# AE612FA0E5597BS0_CM55_HP_View register map
Vendor: Alif Semiconductor; Series: E6; File version: 1.0
CPU: CM55 r1p0, selectable endian, MPU, FPU, double-precision FPU, DSP, VTOR, 8 interrupt priority bits, 1 SAU regions
Registers are 32-bit, read-write, reset 0x0 unless marked. A register's access mark holds for its fields unless they carry their own. Offsets are from the block's base; [hi:lo] are bit positions; 'fields as' and 'values as' point back to an identical list.

## CLKCTL_PER_MST
Base 0x4903F000
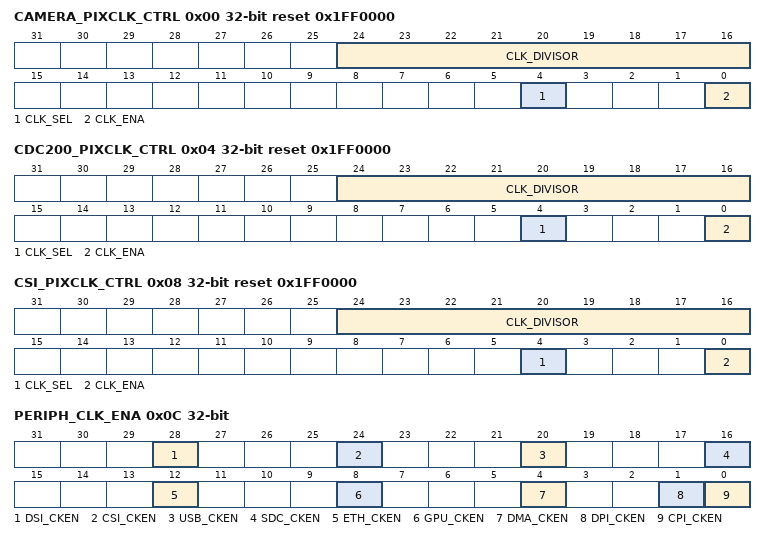
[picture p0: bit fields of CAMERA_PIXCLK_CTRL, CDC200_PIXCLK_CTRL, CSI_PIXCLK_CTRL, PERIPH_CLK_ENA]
0x00 CAMERA_PIXCLK_CTRL reset 0x1FF0000 — CPI Pixel Clock Control Register
  [24:16] CLK_DIVISOR — Pixel clock divisor n: Clock divided by n
    0=Illegal values; 1=Illegal values; 2=Clock divided by 2; 3=Clock divided by 3
  [4] CLK_SEL — Pixel clock select
    0=Select 400 MHz clock source (SYST_ACLK); 1=Select 400 MHz clock source (400M_CLK). If this options is selected, bit CLK_ENA[CLK400M] should be set to enable the 400M_CLK.
  [0] CLK_ENA — Pixel clock enable
    0=Clock disabled; 1=Clock enabled
0x04 CDC200_PIXCLK_CTRL reset 0x1FF0000 — CDC Pixel Clock Control Register
  fields as CAMERA_PIXCLK_CTRL
0x08 CSI_PIXCLK_CTRL reset 0x1FF0000 — CSI Pixel Clock Control Register
  fields as CAMERA_PIXCLK_CTRL
0x0C PERIPH_CLK_ENA — Peripheral Clock Enable Register
  [all] fields
    0=Clock disabled; 1=Clock enabled
  [28] DSI_CKEN — Enable clock for DSI
  [24] CSI_CKEN — Enable clock for CSI
  [20] USB_CKEN — Enable clock for USB
  [16] SDC_CKEN — Enable clock for SDMMC
  [12] ETH_CKEN — Enable clock for ETH
  [8] GPU_CKEN — Enable clock for GPU2D
  [4] DMA_CKEN — Enable clock for DMA0
  [1] DPI_CKEN — Enable clock for DPI controller (CDC)
  [0] CPI_CKEN — Enable clock for CPI
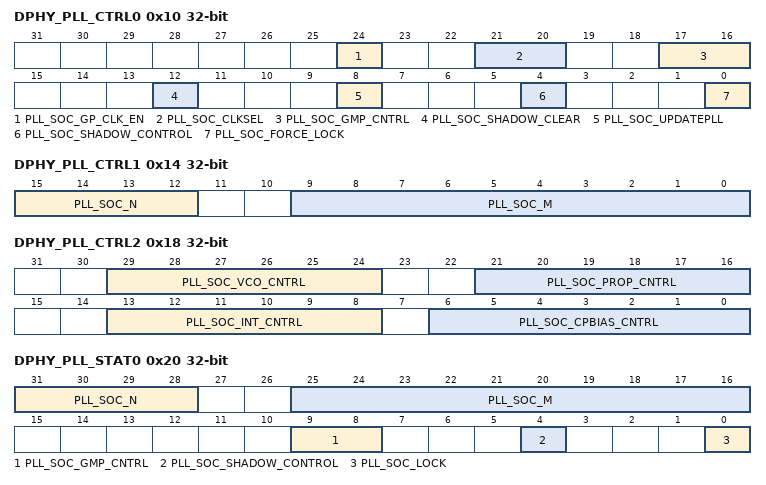
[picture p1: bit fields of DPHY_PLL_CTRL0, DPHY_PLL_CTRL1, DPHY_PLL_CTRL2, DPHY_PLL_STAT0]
0x10 DPHY_PLL_CTRL0 — MIPI-DPHY PLL Control Register 0
  [24] PLL_SOC_GP_CLK_EN — Enable signal for CLKOUT_GP clock
  [21:20] PLL_SOC_CLKSEL — Control of PLL clock output selection
    0=Clocks stopped; 1=Clock generation; 2=Buffered clkext; 3=Forbidden
  [17:16] PLL_SOC_GMP_CNTRL — Controls the effective loop-filter resistance (=1/gmp) to increase/decrease MPLL bandwidth
  [12] PLL_SOC_SHADOW_CLEAR — Shadow registers clear
  [8] PLL_SOC_UPDATEPLL — Control for PLL operation frequency updated
  [4] PLL_SOC_SHADOW_CONTROL — Selection of PLL configuration mechanism
  [0] PLL_SOC_FORCE_LOCK — Force lock to device
0x14 DPHY_PLL_CTRL1 — MIPI-DPHY PLL Control Register 1
  [15:12] PLL_SOC_N — Control of the input frequency division ratio N (1 to 16) for device direct PLL control
  [9:0] PLL_SOC_M — Control of the feedback multiplication ratio M (40 to 625) for device direct PLL control
0x18 DPHY_PLL_CTRL2 — MIPI-DPHY PLL Control Register 2
  [29:24] PLL_SOC_VCO_CNTRL — VCO operating range for device direct PLL control
  [21:16] PLL_SOC_PROP_CNTRL — Proportional charge pump control for device direct PLL control
  [13:8] PLL_SOC_INT_CNTRL — Integral charge pump control for device direct PLL control
  [6:0] PLL_SOC_CPBIAS_CNTRL — Charge pump bias control for device direct PLL control
0x20 DPHY_PLL_STAT0 ro — MIPI-DPHY PLL Status Register 0
  [31:28] PLL_SOC_N — Control of the input frequency division ratio N (1 to 16) for device direct PLL control
  [25:16] PLL_SOC_M — Control of the feedback multiplication ratio M (40 to 625) for device direct PLL control
  [9:8] PLL_SOC_GMP_CNTRL — Control of the effective loop-filter resistance (=1/gmp) to increase/decrease MPLL bandwidth
  [4] PLL_SOC_SHADOW_CONTROL — Selection of PLL configuration mechanism
  [0] PLL_SOC_LOCK — Force lock to device
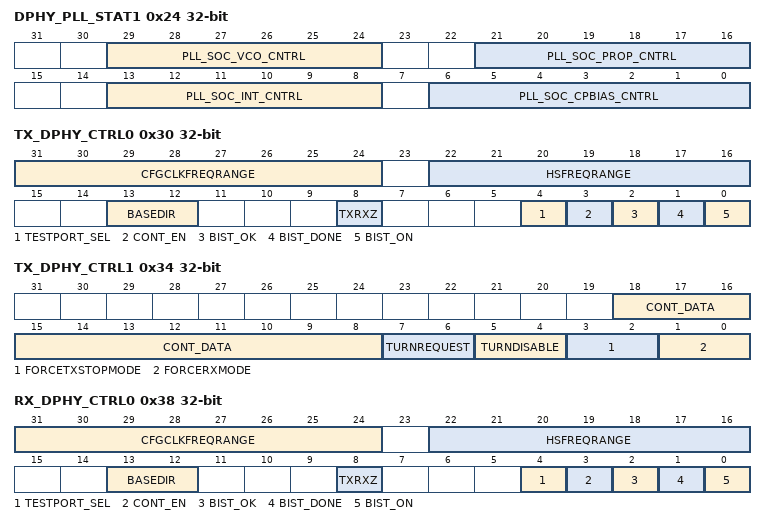
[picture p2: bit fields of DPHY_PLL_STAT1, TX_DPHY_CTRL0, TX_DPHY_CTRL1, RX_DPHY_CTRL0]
0x24 DPHY_PLL_STAT1 ro — MIPI-DPHY PLL Status Register 1
  fields as DPHY_PLL_CTRL2
0x30 TX_DPHY_CTRL0 — MIPI-DPHY TX Control Register 0
  [31:24] CFGCLKFREQRANGE — Input reference clock frequency
  [22:16] HSFREQRANGE — Module operating frequency
    0=Val_0b0000000 (Range - 80-97.125 Mbps; Default Bit Rate - 80 Mbps); 16=Val_0b0010000 (Range - 80-107.625 Mbps; Default Bit Rate - 90 Mbps); 32=Val_0b0100000 (Range - 83.125-118.125 Mbps; Default Bit Rate - 100 Mbps); 48=Val_0b0110000 (Range - 92.625-128.625 Mbps; Default Bit Rate - 110 Mbps); 1=Val_0b0000001 (Range - 102.125-139.125 Mbps; Default Bit Rate - 120 Mbps); 17=Val_0b0010001 (Range - 111.625-149.625 Mbps; Default Bit Rate - 130 Mbps); 33=Val_0b0100001 (Range - 121.125-160.125 Mbps; Default Bit Rate - 140 Mbps); 49=Val_0b0110001 (Range - 130.625-170.625 Mbps; Default Bit Rate - 150 Mbps); 2=Val_0b0000010 (Range - 140.125-181.125 Mbps; Default Bit Rate - 160 Mbps); 18=Val_0b0010010 (Range - 149.625-191.625 Mbps; Default Bit Rate - 170 Mbps); 34=Val_0b0100010 (Range - 159.125-202.125 Mbps; Default Bit Rate - 180 Mbps); 50=Val_0b0110010 (Range - 168.625-212.625 Mbps; Default Bit Rate - 190 Mbps); 3=Val_0b0000011 (Range - 182.875-228.375 Mbps; Default Bit Rate - 205 Mbps); 19=Val_0b0010011 (Range - 197.125-244.125 Mbps; Default Bit Rate - 220 Mbps); 35=Val_0b0100011 (Range - 211.375-259.875 Mbps; Default Bit Rate - 235 Mbps); 51=Val_0b0110011 (Range - 225.625-275.625 Mbps; Default Bit Rate - 250 Mbps); 4=Val_0b0000100 (Range - 249.375-301.875 Mbps; Default Bit Rate - 275 Mbps); 20=Val_0b0010100 (Range - 273.125-328.125 Mbps; Default Bit Rate - 300 Mbps); 37=Val_0b0100101 (Range - 296.875-354.375 Mbps; Default Bit Rate - 325 Mbps); 53=Val_0b0110101 (Range - 320.625-380.625 Mbps; Default Bit Rate - 350 Mbps); 5=Val_0b0000101 (Range - 368.125-433.125 Mbps; Default Bit Rate - 400 Mbps); 22=Val_0b0010110 (Range - 415.625-485.625 Mbps; Default Bit Rate - 450 Mbps); 38=Val_0b0100110 (Range - 463.125-538.125 Mbps; Default Bit Rate - 500 Mbps); 55=Val_0b0110111 (Range - 510.625-590.625 Mbps; Default Bit Rate - 550 Mbps); 7=Val_0b0000111 (Range - 558.125-643.125 Mbps; Default Bit Rate - 600 Mbps); 24=Val_0b0011000 (Range - 605.625-695.625 Mbps; Default Bit Rate - 650 Mbps); 40=Val_0b0101000 (Range - 653.125-748.125 Mbps; Default Bit Rate - 700 Mbps); 57=Val_0b0111001 (Range - 700.625-800.625 Mbps; Default Bit Rate - 750 Mbps); 9=Val_0b0001001 (Range - 748.125-853.125 Mbps; Default Bit Rate - 800 Mbps); 25=Val_0b0011001 (Range - 795.625-905.625 Mbps; Default Bit Rate - 850 Mbps); 41=Val_0b0101001 (Range - 843.125-958.125 Mbps; Default Bit Rate - 900 Mbps); 58=Val_0b0111010 (Range - 890.625-1010.625 Mbps; Default Bit Rate - 950 Mbps); 10=Val_0b0001010 (Range - 938.125-1063.125 Mbps; Default Bit Rate - 1000 Mbps); 26=Val_0b0011010 (Range - 985.625-1115.625 Mbps; Default Bit Rate - 1050 Mbps); 42=Val_0b0101010 (Range - 1033.125-1168.125 Mbps; Default Bit Rate - 1100 Mbps); 59=Val_0b0111011 (Range - 1080.625-1220.625 Mbps; Default Bit Rate - 1150 Mbps); 11=Val_0b0001011 (Range - 1128.125-1273.125 Mbps; Default Bit Rate - 1200 Mbps); 27=Val_0b0011011 (Range - 1175.625-1325.625 Mbps; Default Bit Rate - 1250 Mbps); 43=Val_0b0101011 (Range - 1223.125-1378.125 Mbps; Default Bit Rate - 1300 Mbps); 60=Val_0b0111100 (Range - 1270.625-1430.625 Mbps; Default Bit Rate - 1350 Mbps); 12=Val_0b0001100 (Range - 1318.125-1483.125 Mbps; Default Bit Rate - 1400 Mbps); 28=Val_0b0011100 (Range - 1365.625-1535.625 Mbps; Default Bit Rate - 1450 Mbps); 44=Val_0b0101100 (Range - 1413.125-1588.125 Mbps; Default Bit Rate - 1500 Mbps); 61=Val_0b0111101 (Range - 1460.625-1640.625 Mbps; Default Bit Rate - 1550 Mbps); 13=Val_0b0001101 (Range - 1508.125-1693.125 Mbps; Default Bit Rate - 1600 Mbps); 29=Val_0b0011101 (Range - 1555.625-1745.625 Mbps; Default Bit Rate - 1650 Mbps); 46=Val_0b0101110 (Range - 1603.125-1798.125 Mbps; Default Bit Rate - 1700 Mbps); 62=Val_0b0111110 (Range - 1650.625-1850.625 Mbps; Default Bit Rate - 1750 Mbps); 14=Val_0b0001110 (Range - 1698.125-1903.125 Mbps; Default Bit Rate - 1800 Mbps); 30=Val_0b0011110 (Range - 1745.625-1955.625 Mbps; Default Bit Rate - 1850 Mbps); 47=Val_0b0101111 (Range - 1793.125-2008.125 Mbps; Default Bit Rate - 1900 Mbps); 63=Val_0b0111111 (Range - 1840.625-2060.625 Mbps; Default Bit Rate - 1950 Mbps); 15=Val_0b0001111 (Range - 1888.125-2113.125 Mbps; Default Bit Rate - 2000 Mbps); 64=Val_0b1000000 (Range - 1935.625-2165.625 Mbps; Default Bit Rate - 2050 Mbps); 65=Val_0b1000001 (Range - 1983.125-2218.125 Mbps; Default Bit Rate - 2100 Mbps); 66=Val_0b1000010 (Range - 2030.625-2270.625 Mbps; Default Bit Rate - 2150 Mbps); 67=Val_0b1000011 (Range - 2078.125-2323.125 Mbps; Default Bit Rate - 2200 Mbps); 68=Val_0b1000100 (Range - 2125.625-2375.625 Mbps; Default Bit Rate - 2250 Mbps); 69=Val_0b1000101 (Range - 2173.125-2428.125 Mbps; Default Bit Rate - 2300 Mbps); 70=Val_0b1000110 (Range - 2220.625-2480.625 Mbps; Default Bit Rate - 2350 Mbps); 71=Val_0b1000111 (Range - 2268.125-2500 Mbps; Default Bit Rate - 2400 Mbps); 72=Val_0b1001000 (Range - 2315.625-2500 Mbps; Default Bit Rate - 2450 Mbps); 73=Val_0b1001001 (Range - 2363.125-2500 Mbps; Default Bit Rate - 2500 Mbps)
  [13:12] BASEDIR — Configures the base direction for PHY data lane 0 (bit [12]) and data lane 1 (bit [13]).
    0=Configures lane as TX upon startup of the PHY; 1=Configures lane as RX
  [8] TXRXZ — Selects master or slave configuration for the PHY. The configuration applies to all the PHY lanes (data and clock).
    0=Slave-side D-PHY implementation; 1=Master-side D-PHY implementation
  [4] TESTPORT_SEL — Test port select
    0=Select TX_TESTPORT; 1=Select RX_TESTPORT
  [3] CONT_EN — This bit places the PHY in IO continuity test mode. All other PHY control bits should be placed in their default values.
  [2] BIST_OK ro
  [1] BIST_DONE ro
  [0] BIST_ON
0x34 TX_DPHY_CTRL1 — MIPI-DPHY TX Control Register 1
  [18:8] CONT_DATA ro — Continuity data. Each pin of this output bus is used to verify the continuity from the chips pin all the way to the PHY's analog ports (package, bonding, die, among others).
  [7:6] TURNREQUEST — Controls TURNREQUEST pin of DPHY (bit [6] for data lane 0; bit [7] for data lane 1)
  [5:4] TURNDISABLE — Controls TURNDISABLE pin of DPHY (bit [4] for data lane 0; bit [5] for data lane 1)
  [3:2] FORCETXSTOPMODE — Controls FORCETXSTOPMODE pin of DPHY (bit [2] for data lane 0; bit [3] for data lane 1)
  [1:0] FORCERXMODE — Controls FORCERXMODE pin of DPHY (bit [0] for data lane 0; bit [1] for data lane 1)
0x38 RX_DPHY_CTRL0 — MIPI-DPHY RX Control Register 0
  fields as TX_DPHY_CTRL0
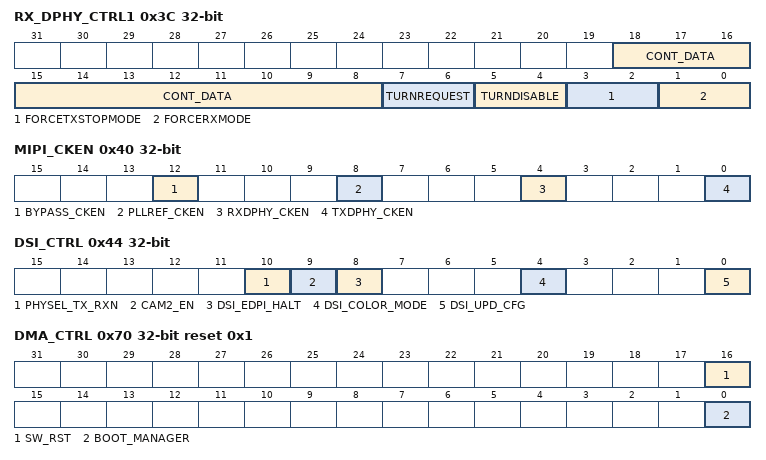
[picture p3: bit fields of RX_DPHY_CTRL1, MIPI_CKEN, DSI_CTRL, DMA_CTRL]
0x3C RX_DPHY_CTRL1 — MIPI-DPHY RX Control Register 1
  fields as TX_DPHY_CTRL1
0x40 MIPI_CKEN — MIPI-DPHY Clock Enable Register
  [12] BYPASS_CKEN — Enable bypass clock for MIPI D-PHY PLL
    0=Disable bypass clock; 1=Enable bypass clock
  [8] PLLREF_CKEN — Enable reference clock for MIPI D-PHY PLL
    0=Disable clock; 1=Enable clock
  [4] RXDPHY_CKEN — Enable configure clock for RX D-PHY
    0=Disable clock; 1=Enable clock
  [0] TXDPHY_CKEN — Enable configure clock for TX D-PHY
    0=Disable clock; 1=Enable clock
0x44 DSI_CTRL — DSI Control Register
  [10] PHYSEL_TX_RXN — DSI PHY direction select
    0=Rx; 1=Tx
  [9] CAM2_EN — Second camera port enable
    0=Disable; 1=Enable
  [8] DSI_EDPI_HALT ro — DSI EDPI halt status
  [4] DSI_COLOR_MODE
    0=Disable; 1=Enable
  [0] DSI_UPD_CFG — DSI update configuration
    0=Disable; 1=Enable
0x70 DMA_CTRL reset 0x1 — DMA0 Boot Control Register
  [16] SW_RST wo — Software reset for DMA0
    0=No reset; 1=Reset DMA0. This bit is self-cleared.
  [0] BOOT_MANAGER — When DMA0 exits from reset, this bit controls the security state of the DMA manager thread
    0=Assigns DMA manager to the secure state; 1=Assigns DMA manager to the non-secure state
0x74 DMA_IRQ reset 0xFFFFFFFF — DMA0 Boot IRQ Non-Secure Register
  [31:0] BOOT_IRQ — Controls the security state of an event-interrupt resource, when DMA0 exits from reset
    0=DMA0 assigns event x or IRQ[x] to the secure state; 1=DMA0 assigns event x or IRQ[x] to the non-secure state
0x78 DMA_PERIPH reset 0xFFFFFFFF — DMA0 Boot Peripheral Non-Secure Register
  [31:0] BOOT_PERIPH — Controls the security state of a peripheral request interface, when DMA0 exits from reset
    0=DMA0 assigns peripheral request interface x to the secure state; 1=DMA0 assigns peripheral request interface x to the non-secure state
0x7C DMA_GLITCH_FLT — DMA0 Glitch Filter Register
  [31:0] ENA — Enable glitch filter for each DMA0 channel. One bit per channel.
    0=Disable the glitch filter; 1=Enable the glitch filter
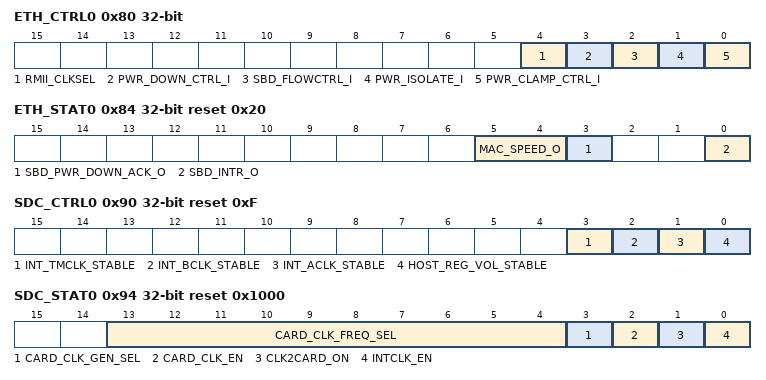
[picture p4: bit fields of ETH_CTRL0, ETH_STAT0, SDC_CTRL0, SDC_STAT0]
0x80 ETH_CTRL0 — ETH Control Register
  [4] RMII_CLKSEL — Select RMII clock source
    0=RMII clock source from ETH_REFCLK pin; 1=RMII clock source from internal 50 MHz PLL clock
  [3] PWR_DOWN_CTRL_I — ETH power down control
    0=Power ON. The whole ETH module is powered-ON.; 1=Power OFF. All ETH blocks are powered-OFF except the always-ON logic.
  [2] SBD_FLOWCTRL_I — ETH sideband flow control When set to 0x1, instructs the MAC to transmit Pause frames in full-duplex mode. In half-duplex mode, the MAC enables the back pressure function until this bit is set to 0x0.
  [1] PWR_ISOLATE_I — Isolation cells enable The isolation cells isolate the signals of the ETH powered-OFF domain from the always-ON domain.
    0=Isolation cells disabled; 1=Isolation cells enabled and provide required signal values to the ETH always-ON domain
  [0] PWR_CLAMP_CTRL_I — ETH always-ON logic reset control
    0=ETH always-ON logic is not in reset (resets are inactive); 1=ETH always-ON logic is in reset (resets are active)
0x84 ETH_STAT0 ro reset 0x20 — ETH Status Register
  [5:4] MAC_SPEED_O — Indicates the MAC speed mode selected
    2=10 Mbps; 3=100 Mbps
  [3] SBD_PWR_DOWN_ACK_O — ETH power-down sequence acknowledge
    0=Power-down not acknowledged. ETH power-down sequence cannot be started.; 1=Power-down acknowledged. ETH power-down sequence can be started.
  [0] SBD_INTR_O — This bit reflects the value of the ETH_SBD_IRQ interrupt
    0=No interrupt; 1=Interrupt
0x88 ETH_PTP_TMST0 ro — ETH Timestamp Register 0
  [31:0] ETH_PTP_TMST — ETH PTP timestamp output value - bits[31-0]
0x8C ETH_PTP_TMST1 ro — ETH Timestamp Register 1
  [31:0] ETH_PTP_TMST — ETH PTP timestamp output value - bits[63-32]
0x90 SDC_CTRL0 reset 0xF — SDMMC Control Register
  [3] INT_TMCLK_STABLE — Internal TMCLK stable Indicates stability of internal clock to SDMMC controller
  [2] INT_BCLK_STABLE — Internal BCLK stable Indicates stability of internal clock to SDMMC controller
  [1] INT_ACLK_STABLE — Internal ACLK stable Indicates stability of internal clock to SDMMC controller
  [0] HOST_REG_VOL_STABLE — Indicates stability of host regulator voltage to SDMMC controller
0x94 SDC_STAT0 ro reset 0x1000 — SDMMC Status Register 0
  [13:4] CARD_CLK_FREQ_SEL — Card clock frequency select
    1=100 MHz; 2=50 MHz; 4=25 MHz; 8=12.5 MHz; 16=6.25 MHz; 32=3.125 MHz; 64=1.56 MHz; 128=781.25 kHz; 0x100=390.625 kHz; 0x200=195.312 kHz
  [3] CARD_CLK_GEN_SEL — Card clock generator mode
    0=Divided clock mode; 1=Programmable clock mode
  [2] CARD_CLK_EN — Card clock PLL enable
  [1] CLK2CARD_ON — Control to switch on clock supplied to the card
  [0] INTCLK_EN — Internal clock request. When this is 0, ACLK and BCLK can be stopped.
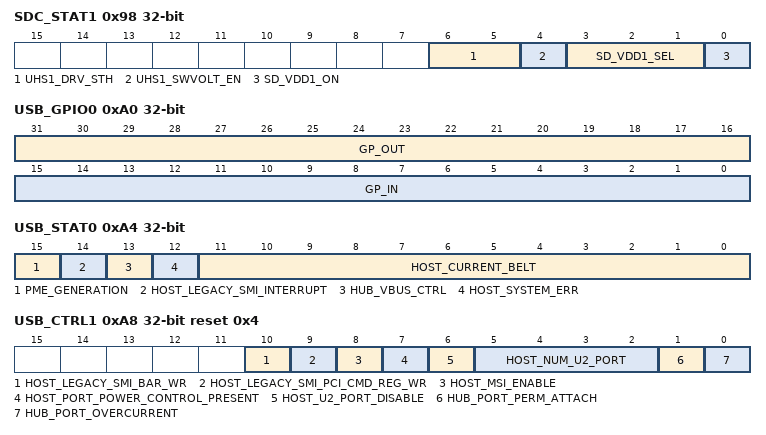
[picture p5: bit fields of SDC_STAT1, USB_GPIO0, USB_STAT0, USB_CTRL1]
0x98 SDC_STAT1 ro — SDMMC Status Register 1
  [6:5] UHS1_DRV_STH — UHS-I driver strength select Host controller indicates output driver strength in 1.8-V signaling. In 3.3-V signaling, this output is not effective.
    0=Driver Type B (Default); 1=Driver Type A; 2=Driver Type C; 3=Driver Type D
  [4] UHS1_SWVOLT_EN — Switch voltage from 3.3 V to 1.8 V for UHS-I This bit is a command to external voltage regulator to switch voltage from 3.3V to 1.8V.
    0=3.3-V SD card signaling; 1=1.8-V SD card signaling
  [3:1] SD_VDD1_SEL — Select VDD1 voltage level for SD card/eMMC
    5=1.8V; 6=3.0V; 7=3.3V
  [0] SD_VDD1_ON — Switch on VDD1/VDD bus power for SD card/eMMC
0xA0 USB_GPIO0 — USB GPIO Register
  [31:16] GP_OUT ro — USB GPIO output. Values written to the USB module GGPIO[GPO] field can be read from this field.
  [15:0] GP_IN — USB GPIO input. Values written to this field can be read from the USB module GGPIO[GPI] field.
0xA4 USB_STAT0 ro — USB Status Register
  [15] PME_GENERATION — PME generation output
  [14] HOST_LEGACY_SMI_INTERRUPT — Host legacy SMI interrupt output
  [13] HUB_VBUS_CTRL — Host VBUS control output
  [12] HOST_SYSTEM_ERR — Host system error output
  [11:0] HOST_CURRENT_BELT — Host current belt output
0xA8 USB_CTRL1 reset 0x4 — USB Control Register 1
  [10] HOST_LEGACY_SMI_BAR_WR — PCI Base Address Register (BAR) write: one clock pulse. The PCIe interface need to generate one clock pulse during PCIe BAR write.
  [9] HOST_LEGACY_SMI_PCI_CMD_REG_WR — PCI command register write: one clock pulse. The PCIe interface needs to generate one clock pulse during PCIe command register write.
  [8] HOST_MSI_ENABLE — This enables the pulse type interrupt signal (one bus clock cycle) interrupt port instead of level-sensitive interrupt. When interfacing to PCIe, this allows the user to easily map interrupt to MSI in the PCIe controller.
  [7] HOST_PORT_POWER_CONTROL_PRESENT — This bit defines the bit [3] of Capability Parameters (HCCPARAMS). This indicates whether the host controller implementation includes port power control.
    0=Port does not have port power switches; 1=Port has port power switches
  [6] HOST_U2_PORT_DISABLE — USB 2.0 Port Disable Control This bit should either be static (should not change during operation) or change only once from 0x0 to 0x1 during operation and stay at 0x1 after that.
    0=Port enabled; 1=Port disabled
  [5:2] HOST_NUM_U2_PORT — Number of USB 2.0 ports
  [1] HUB_PORT_PERM_ATTACH — Indicates if the device attached to a downstream port is permanently attached or not
    0=Not permanently attached; 1=Permanently attached
  [0] HUB_PORT_OVERCURRENT — This is the port over-current indication of the root-hub ports
    0=No over-current; 1=Over-current
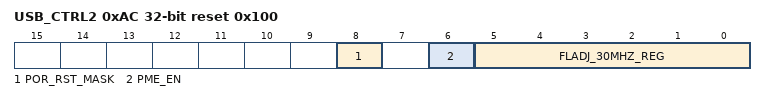
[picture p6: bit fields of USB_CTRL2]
0xAC USB_CTRL2 reset 0x100 — USB Control Register 2
  [8] POR_RST_MASK — Active-high USB PHY PoR reset mask. Must be set/cleared during PHY power-down/up sequence.
  [6] PME_EN — Power management enable of USB
  [5:0] FLADJ_30MHZ_REG — Frequency adjust value of USB
